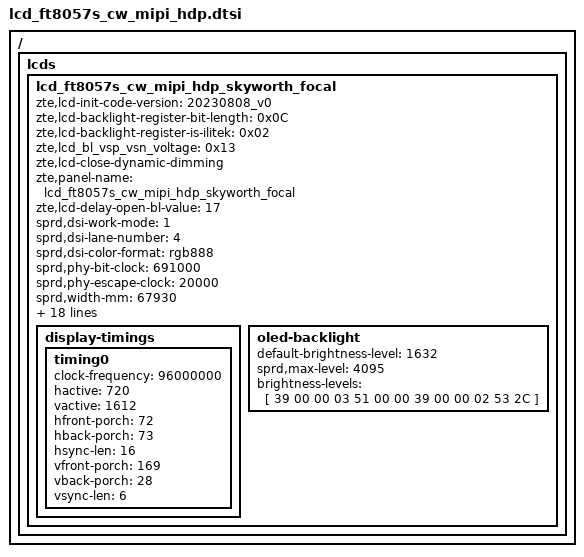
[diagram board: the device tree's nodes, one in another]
/ { 
	fragment {
		target-path = "/";
		__overlay__ {
			lcds {
				lcd_ft8057s_cw_mipi_hdp_skyworth_focal: lcd_ft8057s_cw_mipi_hdp_skyworth_focal {
		zte,lcd-init-code-version = "20230808_v0";
		zte,lcd-backlight-register-bit-length = <0x0C>;
		zte,lcd-backlight-register-is-ilitek = <0x02>;/*51h=0xff0f*/
		zte,lcd_bl_vsp_vsn_voltage = <0x13>;
		/*zte,lcd-disable-ssc;*/
		zte,lcd-close-dynamic-dimming;
		zte,panel-name = "lcd_ft8057s_cw_mipi_hdp_skyworth_focal";
		zte,lcd-delay-open-bl-value = <17>;

					sprd,dsi-work-mode = <1>;
					sprd,dsi-lane-number = <4>;
					sprd,dsi-color-format = "rgb888";

					sprd,phy-bit-clock = <691000>;
					sprd,phy-escape-clock = <20000>;

					sprd,width-mm = <67930>;/*zte mod for 6.56*/
					sprd,height-mm = <152090>;/*zte mod for 6.56*/

					sprd,esd-check-enable = <1>;
					sprd,esd-check-mode = <1>;
					sprd,esd-check-period = <2000>;
					sprd,esd-check-register = <0x0A>;
					sprd,esd-check-value = <0x9C>;

					sprd,lcm-ic-name = "FT8057S";
					sprd,lcm-ic-vendor = "CW";
					sprd,lcm-ic-inch = "6.56";

					sprd,reset-on-sequence = <1 15>, <0 15>, <1 50>;
					sprd,reset-off-sequence = <1 5>;

					sprd,initial-command = [
							23 00 00 02 00 00
							39 00 00 04 FF 80 57 01
							23 00 00 02 00 80
							39 00 00 03 FF 80 57
							23 00 00 02 00 AD
							39 00 00 03 C1 AA AA
							23 00 00 02 00 00
							39 00 00 05 2A 00 00 02 CF //720
							23 00 00 02 00 00
							39 00 00 05 2B 00 00 06 4B //1612
							23 00 00 02 00 A3 //Y=1612
							39 00 00 05 B3 06 4C 00 18
							//--------------Voltageset--------------//
							23 00 00 02 00 93 //VGH_N16V
							23 00 00 02 C5 61
							23 00 00 02 00 97 //VGH_I16V
							23 00 00 02 C5 61
							23 00 00 02 00 9A //VGL_N-11V
							23 00 00 02 C5 37
							23 00 00 02 00 9C //VGL_I-11V
							23 00 00 02 C5 37
							23 00 00 02 00 B6 //VGHO1_N_I=15v
							39 00 00 03 C5 4D 4D
							23 00 00 02 00 B8 //VGLO1_N_I-10V
							39 00 00 03 C5 2D 2D
							23 00 00 02 00 00
							39 00 00 03 D8 35 35 //GVDDP/N5.5V-5.5V
							23 00 00 02 00 82
							23 00 00 02 C5 55 //LVD
							23 00 00 02 00 83
							23 00 00 02 C5 07 //LVDEnable
							//Vgh_s_sel>>vgh
							23 00 00 02 00 86
							23 00 00 02 f5 0d
							//Vgl_s_sel>>vgl
							23 00 00 02 00 96
							23 00 00 02 f5 0d
							//VGHCLKLineRate(1Line)
							23 00 00 02 00 94
							23 00 00 02 C5 15
							//VGLCLKLineRate(1Line)
							23 00 00 02 00 9B
							23 00 00 02 C5 51
							23 00 00 02 00 A3 //GVDD_EN
							23 00 00 02 A5 04
							23 00 00 02 00 99
							23 00 00 02 CF 56
							23 00 00 02 00 86
							23 00 00 02 B7 80 //I2C EN
							23 00 00 02 00 A5
							23 00 00 02 B0 1D //RCdelay95ns

							//--------------TCONsetting--------------//
							//TCON
							23 00 00 02 00 80
							39 00 00 07 C0 00 7F 00 2A 00 1C
							23 00 00 02 00 90
							39 00 00 07 C0 00 D2 00 2A 00 1C
							23 00 00 02 00 A0
							39 00 00 07 C0 00 7F 00 2A 00 1C
							23 00 00 02 00 B0
							39 00 00 06 C0 01 10 00 2A 1C
							23 00 00 02 00 C1
							39 00 00 09 C0 01 33 01 0A 00 CD 01 90
							23 00 00 02 00 70
							39 00 00 07 C0 00 D2 00 2A 00 1C
							23 00 00 02 00 A3
							39 00 00 07 C1 00 3C 00 33 00 02
							23 00 00 02 00 B7
							39 00 00 03 C1 00 3C
							23 00 00 02 00 73
							39 00 00 03 CE 09 09
							23 00 00 02 00 80
							39 00 00 11 CE 01 81 09 09 00 78 00 96 00 78 00 96 00 78 00 96
							23 00 00 02 00 90
							39 00 00 10 CE 00 A5 16 8F 00 A5 80 09 09 00 07 D0 17 17 16
							23 00 00 02 00 A0
							39 00 00 04 CE 20 00 00
							23 00 00 02 00 B0
							39 00 00 04 CE 87 00 00
							23 00 00 02 00 D1
							39 00 00 08 CE 00 00 01 00 00 00 00
							23 00 00 02 00 E1
							39 00 00 0C CE 08 02 B0 02 B0 03 C3 00 00 00 00

							23 00 00 02 00 F1
							39 00 00 0A CE 1E 1E 14 01 45 01 45 01 45

							23 00 00 02 00 B0
							39 00 00 05 CF 00 00 65 69

							23 00 00 02 00 B5
							39 00 00 05 CF 03 03 53 57

							23 00 00 02 00 C0
							39 00 00 05 CF 06 06 47 4B

							23 00 00 02 00 C5
							39 00 00 05 CF 06 06 4B 4F

							23 00 00 02 00 60
							39 00 00 09 CF 00 00 65 69 03 03 53 57

							23 00 00 02 00 70
							39 00 00 09 CF 00 00 6D 71 03 03 5B 5F

							23 00 00 02 00 AA
							39 00 00 05 CF 80 80 1C 18

							//QsyncDetect
							23 00 00 02 00 D1
							39 00 00 0D C1 03 AA 05 22 09 59 05 87 08 23 0F AC

							23 00 00 02 00 E1
							39 00 00 03 C1 05 22

							23 00 00 02 00 E2
							39 00 00 0D CF 06 DA 06 D9 06 D9 06 D9 06 D9 06 D9

							//OSC
							23 00 00 02 00 80
							39 00 00 03 C1 00 00

							23 00 00 02 00 90
							23 00 00 02 C1 01

							//LinerateforTP
							23 00 00 02 00 F5
							23 00 00 02 CF 02

							//TPFramerate
							23 00 00 02 00 F6
							23 00 00 02 CF 3C

							//TCONFramerate
							23 00 00 02 00 F1
							23 00 00 02 CF 3C

							//ModeswitchbyCMD2
							23 00 00 02 00 F7
							23 00 00 02 CF 71

							23 00 00 02 00 00
							39 00 00 03 1F 3C 3C
							//VBMode1.2ms
							23 00 00 02 00 D1
							39 00 00 08 CE 00 10 01 01 00 99 01

							23 00 00 02 00 E8
							39 00 00 05 CE 00 99 00 99

							//--------------CGOUTsetting--------------//
							//U2Dmapping
							//CGOUTL
							23 00 00 02 00 80
							39 00 00 11 CC 00 00 17 01 03 05 21 1E 07 07 09 09 0B 0B 0D 0D

							23 00 00 02 00 90
							39 00 00 09 CC 0F 0F 11 11 00 00 00 00

							//CGOUTR
							23 00 00 02 00 80
							39 00 00 11 CD 00 00 16 01 02 04 20 1E 06 06 08 08 0A 0A 0C 0C

							23 00 00 02 00 90
							39 00 00 09 CD 0E 0E 10 10 00 00 00 00

							//--------------GIPsetting--------------//
							//poweroffenmodesetting
							23 00 00 02 00 80
							39 00 00 11 CB C1 C1 C1 C1 C1 C1 C1 C1 C1 C1 C1 C1 CF C1 C1 C1

							23 00 00 02 00 ED
							23 00 00 02 CB C1

							//poweronenmodesetting
							23 00 00 02 00 90
							39 00 00 11 CB 00 00 00 00 00 00 00 00 00 00 00 00 FC 00 00 00

							23 00 00 02 00 EE
							23 00 00 02 CB 00

							23 00 00 02 00 90
							23 00 00 02 C3 00

							//skip&powron1enmodesetting
							23 00 00 02 00 A0
							39 00 00 09 CB 00 00 00 00 00 00 00 00

							//poweroffblankenmodesetting
							23 00 00 02 00 B0
							39 00 00 05 CB 55 55 55 D5
							//poweronblankenmodesetting
							23 00 00 02 00 C0
							39 00 00 05 CB 55 55 55 D5

							//poweronblankenmodesetting
							23 00 00 02 00 D2
							39 00 00 0C CB 83 00 83 83 00 83 83 00 83 83 00

							23 00 00 02 00 E0
							39 00 00 0E CB 83 83 00 83 83 00 83 83 00 83 83 00 83

							23 00 00 02 00 FA
							39 00 00 03 CB 83 00

							23 00 00 02 00 EF
							23 00 00 02 CB 00

							//STV1
							23 00 00 02 00 68
							39 00 00 05 C2 8D 05 00 00
							//STV2
							23 00 00 02 00 6C
							39 00 00 05 C2 8C 05 00 00
							//STV3
							23 00 00 02 00 70
							39 00 00 05 C2 8B 05 00 00
							//STV4
							23 00 00 02 00 74
							39 00 00 05 C2 8A 05 00 00

							//GOFF1
							23 00 00 02 00 E0
							39 00 00 05 C3 00 00 00 00

							//GOFF2
							23 00 00 02 00 E4
							39 00 00 05 C3 00 00 00 00


							23 00 00 02 00 FE //GOFF1&GOFF2EnableVSTFunction
							23 00 00 02 CB A0

							23 00 00 02 00 F5 //GOFF1/GOFF2addVST4shift&width
							39 00 00 04 CD 89 55 88

							//VEND1
							23 00 00 02 00 78
							39 00 00 05 C2 06 05 00 00
							//VEND2
							23 00 00 02 00 7C
							39 00 00 05 C2 07 05 00 00

							//RST1
							23 00 00 02 00 EA
							39 00 00 09 C2 12 00 0E 0E 00 00 00 00

							//CKV1
							23 00 00 02 00 8C
							39 00 00 06 C2 8B 04 05 7E 68
							//CKV2
							23 00 00 02 00 91
							39 00 00 06 C2 8A 05 05 7E 68
							//CKV3
							23 00 00 02 00 96
							39 00 00 06 C2 89 06 05 7E 68
							//CKV4
							23 00 00 02 00 9B
							39 00 00 06 C2 88 07 05 7E 68

							//CKV5
							23 00 00 02 00 A0
							39 00 00 06 C2 87 00 05 7E 68
							//CKV6
							23 00 00 02 00 A5
							39 00 00 06 C2 86 00 05 7E 68
							//CKV7
							23 00 00 02 00 AA
							39 00 00 06 C2 85 00 05 7E 68
							//CKV8
							23 00 00 02 00 AF
							39 00 00 06 C2 84 00 05 7E 68

							//CKV9
							23 00 00 02 00 B4
							39 00 00 06 C2 83 01 05 7E 68
							//CKV10
							23 00 00 02 00 B9
							39 00 00 06 C2 82 02 05 7E 68
							//CKV11
							23 00 00 02 00 BE
							39 00 00 06 C2 81 03 05 7E 68
							//CKV12
							23 00 00 02 00 C3
							39 00 00 06 C2 80 04 05 7E 68

							//CKVwidthsetting
							23 00 00 02 00 dc
							39 00 00 09 C2 bb bb bb bb bb bb 00 00

							//--------------Sourcesetting--------------//
							23 00 00 02 00 98
							23 00 00 02 C4 08

							23 00 00 02 00 91
							39 00 00 05 E9 FF FF FF 00

							23 00 00 02 00 85 //Posdmypch
							23 00 00 02 C4 80

							23 00 00 02 00 86 //4VBpch
							23 00 00 02 A4 B6

							23 00 00 02 00 95 //VBpchdata
							23 00 00 02 C4 80

							//--------------Poweron&off--------------//
							23 00 00 02 00 CA //Poweron3
							39 00 00 03 C0 90 11

							23 00 00 02 00 B7 //sd_en_sdpl_sel
							23 00 00 02 F5 1D

							23 00 00 02 00 90
							23 00 00 02 C3 00

							23 00 00 02 00 B1 //VCOM
							23 00 00 02 F5 11

							//--------------sleepinallgateon--------------//
							23 00 00 02 00 B0
							23 00 00 02 C5 00

							23 00 00 02 00 B3
							23 00 00 02 C5 00

							23 00 00 02 00 B2
							23 00 00 02 C5 0D

							23 00 00 02 00 B5
							23 00 00 02 C5 02

							23 00 00 02 00 C2
							23 00 00 02 F5 42
							//*********************************************//
							//*********************************************//
							//LongVmode
							23 00 00 02 00 80
							23 00 00 02 CE 00

							23 00 00 02 00 D0
							23 00 00 02 CE 01

							23 00 00 02 00 E0
							23 00 00 02 CE 00

							23 00 00 02 00 A1
							23 00 00 02 C1 CC

							23 00 00 02 00 A6
							23 00 00 02 C1 10

							23 00 00 02 00 71 //VFP=169-1
							39 00 00 06 C0 FB 00 A8 00 24

							23 00 00 02 00 81 //sourcechop
							23 00 00 02 A4 73

							23 00 00 02 00 B0 //PWM12bit//13.43Khz
							39 00 00 04 CA 01 01 0C
							23 00 00 02 00 B5 //PWMdimmingframenumber16
							23 00 00 02 CA 04
							23 00 00 02 00 BC
							39 00 00 03 C5 01 01
							23 00 00 02 35 00 //TE
							23 00 00 02 00 89 //IBIAS_SAPX0.9current
							39 00 00 04 C5 06 06 06
							23 00 00 02 00 84 //IBIAS_APX0.9current
							23 00 00 02 C5 66
							23 00 00 02 00 86 //CKVEQ
							39 00 00 04 C3 0F 00 00
							//--------------CMDWRDisable--------------//
							23 00 00 02 00 00
							39 00 00 04 FF 00 00 00

							23 00 00 02 00 80
							39 00 00 03 FF 00 00

							//----------------------LCDinitialcodeEnd----------------------//
							39 00 00 03 51 FF 0F
							23 00 00 02 53 2C
							23 00 00 02 55 00
							23 00 00 02 35 00
							13 96 00 01 11
							13 32 00 01 29
					];
					sprd,sleep-in-command = [
						13 32 00 01 28
						13 96 00 01 10
					];
					sprd,sleep-out-command = [
						13 96 00 01 11
						13 32 00 01 29
					];
					sprd,sleep-in-command2 = [
						13 32 00 01 28
					];

					display-timings {
						timing0{
							clock-frequency = <96000000>;
							hactive = <720>;
							vactive = <1612>;
							hfront-porch = <72>;
							hback-porch = <73>;
							hsync-len = <16>;
							vfront-porch = <169>;
							vback-porch = <28>;
							vsync-len = <6>;
						};
					};
				/*#include "./blacklight_params.dtsi"*/
				oled-backlight {
					default-brightness-level = <1632>;
					sprd,max-level = <4095>;
					brightness-levels = [
						39 00 00 03 51 00 00
						39 00 00 02 53 2C
						];
					};
				};
			};
		};
	};
};
